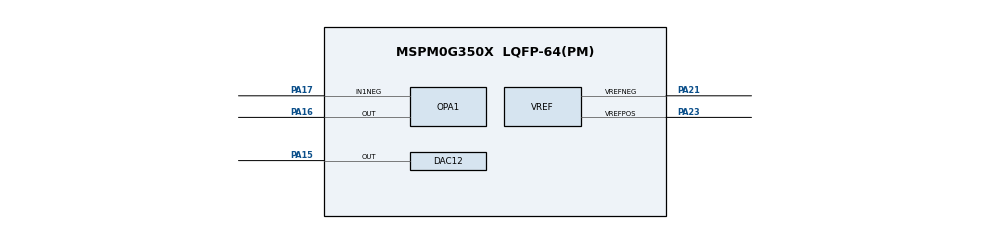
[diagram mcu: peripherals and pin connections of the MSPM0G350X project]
// @cliArgs --device "MSPM0G350X" --package "LQFP-64(PM)" --part "Default"
// @cliArgs --board /ti/boards/LP_MSPM0G3507 --rtos nortos

/**
 * Import the modules used in this configuration.
 */
const Board  = scripting.addModule("/ti/driverlib/Board");
const DAC12  = scripting.addModule("/ti/driverlib/DAC12");
const OPA    = scripting.addModule("/ti/driverlib/OPA", {}, false);
const OPA1   = OPA.addInstance();
const SYSCTL = scripting.addModule("/ti/driverlib/SYSCTL");
const VREF   = scripting.addModule("/ti/driverlib/VREF");

/**
 * Write custom configuration values to the imported modules.
 */
const gate8  = system.clockTree["MFPCLKGATE"];
gate8.enable = true;

Board.InitPriority21 = "/ti/driverlib/OPA";

DAC12.dacPosVREF                = "VEREFP";
DAC12.dacNegVREF                = "VEREFN";
DAC12.dacOutputPinEn            = true;
DAC12.dacOutput12               = 2043;
DAC12.dacAmplifier              = "ON";
DAC12.peripheral.$assign        = "DAC0";
DAC12.peripheral.OutPin.$assign = "PA15";

OPA1.$name                        = "OPA_0";
OPA1.cfg0PSELChannel              = "DAC_OUT";
OPA1.cfg0NSELChannel              = "RTAP";
OPA1.cfg0MSELChannel              = "IN1_NEG";
OPA1.cfg0OutputPin                = "ENABLED";
OPA1.cfg0Gain                     = "N15_P16";
OPA1.advBW                        = "HIGH";
OPA1.peripheral.$assign           = "OPA1";
OPA1.peripheral.In1NegPin.$assign = "PA17";
OPA1.peripheral.OutPin.$assign    = "PA16";

SYSCTL.MFPCLKEn = true;

VREF.advClockConfigEnable          = true;
VREF.advClkSrc                     = "DL_VREF_CLOCK_BUSCLK";
VREF.basicIntVolt                  = "DL_VREF_BUFCONFIG_OUTPUT_2_5V";
VREF.checkVREFReady                = true;
VREF.basicVrefPins                 = "VREF+-";
VREF.peripheral.$assign            = "VREF";
VREF.peripheral.vrefPosPin.$assign = "PA23";
VREF.peripheral.vrefNegPin.$assign = "PA21";

SYSCTL.forceDefaultClkConfig = true;
SYSCTL.clockTreeEn  = true;
